AUTOSAR XML (schema 4-2-2)
package /ComponentTypes
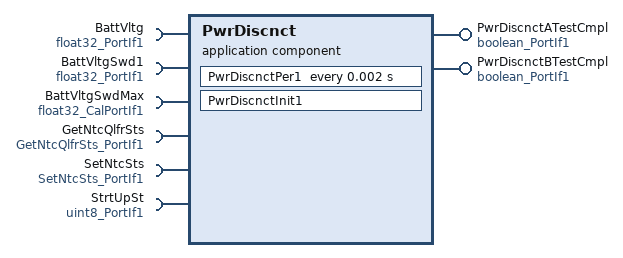
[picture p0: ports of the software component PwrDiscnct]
  application sw component type PwrDiscnct
    provide port PwrDiscnctATestCmpl: nonqueued-sender-com-spec{data-element=Logl, init-value=0}, provided-interface=boolean_PortIf1  # Flag indicating that the Power Disconnect Sequence A is complete or not
    provide port PwrDiscnctBTestCmpl: nonqueued-sender-com-spec{data-element=Logl, init-value=0}, provided-interface=boolean_PortIf1  # Flag indicating that the Power Disconnect Sequence B is complete or not
    6 x require port:
      BattVltg: nonqueued-receiver-com-spec{data-element=Val, filter=data-filter-type=ALWAYS, init-value=0}, required-interface=float32_PortIf1  # Battery Voltage
      BattVltgSwd1: nonqueued-receiver-com-spec{data-element=Val, filter=data-filter-type=ALWAYS, init-value=0}, required-interface=float32_PortIf1  # Switched Battery Voltage 1
      BattVltgSwdMax: parameter-require-com-spec{init-value=16, parameter=Val}, required-interface=float32_CalPortIf1  # Maximum voltage at which switched voltage saturates
      GetNtcQlfrSts: client-com-spec=Oper, required-interface=GetNtcQlfrSts_PortIf1
      SetNtcSts: client-com-spec=Oper, required-interface=SetNtcSts_PortIf1
      StrtUpSt: nonqueued-receiver-com-spec{data-element=Val, filter=data-filter-type=ALWAYS, init-value=0}, required-interface=uint8_PortIf1  # Start Up State
    behavior PwrDiscnct_InternalBehavior
      ar-typed-per-instance-memorys:
        data PwrDiscnctATestCmplPrev: sw-calibration-access=READ-ONLY, type=boolean  # Power Disconnect First Run Complete - Determines if the PwrDiscnctSequenceA has computes once per IGN Cycle
      init event PwrDiscnct_InitEvent: start-on-event=PwrDiscnctInit1
      timing event TMT_PwrDiscnctPer1: start-on-event=PwrDiscnctPer1, period=0.002
      runnable PwrDiscnctInit1
      runnable PwrDiscnctPer1
        data-receive-point-by-arguments:
          access REC_BattVltg_Val: accessed-variable=BattVltg.Val
          access REC_BattVltgSwd1_Val: accessed-variable=BattVltgSwd1.Val
          access REC_StrtUpSt_Val: accessed-variable=StrtUpSt.Val
        data-send-points:
          access SEND_PwrDiscnctATestCmpl_Logl_1: accessed-variable=PwrDiscnctATestCmpl.Logl
          access SEND_PwrDiscnctBTestCmpl_Logl_1: accessed-variable=PwrDiscnctBTestCmpl.Logl
        sync call SC_GetNtcQlfrSts_Oper: operation=GetNtcQlfrSts.Oper, timeout=0
        sync call SC_SetNtcSts_Oper: operation=SetNtcSts.Oper, timeout=0
  swc implementation PwrDiscnct_Implementation: behavior=PwrDiscnct_InternalBehavior
    code-descriptors:
      code Default: artifact-descriptors=autosar-engineering-object={short-label=Default, category=SWSRC}
